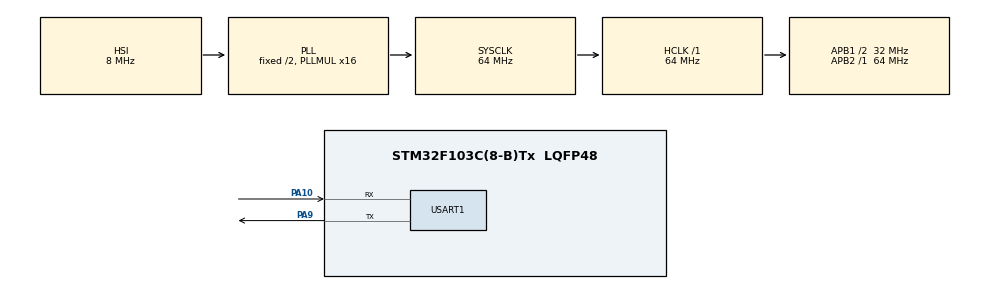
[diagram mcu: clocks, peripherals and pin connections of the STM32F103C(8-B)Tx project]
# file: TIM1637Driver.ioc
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Mcu.Family=STM32F1
Mcu.Name=STM32F103C(8-B)Tx
Mcu.Package=LQFP48
NVIC.PriorityGroup=NVIC_PRIORITYGROUP_4
PA10.Mode=Asynchronous
PA10.Signal=USART1_RX
PA13.Mode=Serial_Wire
PA13.Signal=SYS_JTMS-SWDIO
PA14.Mode=Serial_Wire
PA14.Signal=SYS_JTCK-SWCLK
PA9.Mode=Asynchronous
PA9.Signal=USART1_TX
PC14-OSC32_IN.Mode=LSE-External-Oscillator
PC14-OSC32_IN.Signal=RCC_OSC32_IN
PC15-OSC32_OUT.Mode=LSE-External-Oscillator
PC15-OSC32_OUT.Signal=RCC_OSC32_OUT
ProjectManager.HeapSize=0x200
ProjectManager.StackSize=0x400
ProjectManager.TargetToolchain=Makefile
RCC.AHBFreq_Value=64000000
RCC.APB1CLKDivider=RCC_HCLK_DIV2
RCC.APB1Freq_Value=32000000
RCC.APB1TimFreq_Value=64000000
RCC.APB2Freq_Value=64000000
RCC.APB2TimFreq_Value=64000000
RCC.HCLKFreq_Value=64000000
RCC.PLLMUL=RCC_PLL_MUL16
RCC.SYSCLKFreq_VALUE=64000000
RCC.SYSCLKSource=RCC_SYSCLKSOURCE_PLLCLK
RCC.USBFreq_Value=64000000
USART1.VirtualMode=VM_ASYNC
board=custom

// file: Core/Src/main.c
/* USER CODE BEGIN Header */
/**
  ******************************************************************************
  * @file           : main.c
  * @brief          : Main program body
  ******************************************************************************
  * @attention
  *
  * <h2><center>&copy; Copyright (c) 2024 STMicroelectronics.
  * All rights reserved.</center></h2>
  *
  * This software component is licensed by ST under BSD 3-Clause license,
  * the "License"; You may not use this file except in compliance with the
  * License. You may obtain a copy of the License at:
  *                        opensource.org/licenses/BSD-3-Clause
  *
  ******************************************************************************
  */
/* USER CODE END Header */
#include "main.h"

/* USER CODE BEGIN Includes */
#include "tim1637.h"
#include <string.h>
#include <stdio.h>
/* USER CODE END Includes */

UART_HandleTypeDef huart1;

void SystemClock_Config(void);
static void MX_GPIO_Init(void);
static void MX_USART1_UART_Init(void);

/* USER CODE BEGIN 0 */
void config_my_tim(CCGPIO* CLK, CCGPIO* DIO){
    createGPIO(CLK, GPIOB, GPIO_PIN_6, 'B');
    createGPIO(DIO, GPIOB, GPIO_PIN_7, 'B');
    CCGPIOConfig config;
    createGPIOConfig(&config, GPIO_SPEED_FREQ_HIGH, GPIO_NOPULL, GPIO_MODE_OUTPUT_PP);
    setGPIOConfig(CLK, &config);
    setGPIOConfig(DIO, &config);
}

void config_my_tim2(CCGPIO* CLK, CCGPIO* DIO){
    createGPIO(CLK, GPIOA, GPIO_PIN_6, 'A');
    createGPIO(DIO, GPIOA, GPIO_PIN_7, 'A');
    CCGPIOConfig config;
    createGPIOConfig(&config, GPIO_SPEED_FREQ_HIGH, GPIO_NOPULL, GPIO_MODE_OUTPUT_PP);
    setGPIOConfig(CLK, &config);
    setGPIOConfig(DIO, &config);
}

void adjust_num(uint8_t disp[]){
  // the two and third one is seconds
  disp[3]++;
  if(disp[3] >= 10){
    disp[2] += 1;
    disp[3] = 0;
  }

  if(disp[2] >= 6)
  {
    disp[1] += 1;
    disp[2] = 0;
  }

    if(disp[1] >= 10){
    disp[0] += 1;
    disp[1] = 0;
  }
}

/* USER CODE END 0 */

int main(void)
{

  /* MCU Configuration--------------------------------------------------------*/

  /* Reset of all peripherals, Initializes the Flash interface and the Systick. */
  HAL_Init();

  /* Configure the system clock */
  SystemClock_Config();

  /* Initialize all configured peripherals */
  MX_GPIO_Init();
  MX_USART1_UART_Init();

  /* Infinite loop */
  /* USER CODE BEGIN WHILE */

  DisplayArray arr;
  CCGPIO CLK, DIO, CLK2, DIO2;
  CCTIM1637_Handle handle, handle2;
  config_my_tim(&CLK, &DIO);
  config_my_tim2(&CLK2, &DIO2);
  init_cctim1637(&handle, &CLK, &DIO);
  init_cctim1637(&handle2, &CLK2, &DIO2);
  set_TIM1637_Brightness(&handle, 7);
  set_TIM1637_Brightness(&handle2, 3);
  uint8_t shell_disp = 1;
  uint8_t disp_num[4] = {0, 0, 0, 0};
  while (1)
  {
    /* USER CODE END WHILE */

    /* USER CODE BEGIN 3 */
    set_display_array_at_index(disp_num[0] , arr, 0);
    set_display_array_at_index(disp_num[1], arr, 1);
    set_accuired_disp_colon(arr, shell_disp);
    set_display_array_at_index(disp_num[2], arr, 2);
    set_display_array_at_index(disp_num[3], arr, 3);
    commit_display_auto_upgrade(&handle, arr);
    commit_display_auto_upgrade(&handle2, arr);
    HAL_Delay(1000);
    shell_disp = !shell_disp;
    adjust_num(disp_num);
  }
  /* USER CODE END 3 */
}

void SystemClock_Config(void)
{
  RCC_OscInitTypeDef RCC_OscInitStruct = {0};
  RCC_ClkInitTypeDef RCC_ClkInitStruct = {0};

  /** Initializes the RCC Oscillators according to the specified parameters
  * in the RCC_OscInitTypeDef structure.
  */
  RCC_OscInitStruct.OscillatorType = RCC_OSCILLATORTYPE_HSI;
  RCC_OscInitStruct.HSIState = RCC_HSI_ON;
  RCC_OscInitStruct.HSICalibrationValue = RCC_HSICALIBRATION_DEFAULT;
  RCC_OscInitStruct.PLL.PLLState = RCC_PLL_ON;
  RCC_OscInitStruct.PLL.PLLSource = RCC_PLLSOURCE_HSI_DIV2;
  RCC_OscInitStruct.PLL.PLLMUL = RCC_PLL_MUL16;
  if (HAL_RCC_OscConfig(&RCC_OscInitStruct) != HAL_OK)
  {
    Error_Handler();
  }
  /** Initializes the CPU, AHB and APB buses clocks
  */
  RCC_ClkInitStruct.ClockType = RCC_CLOCKTYPE_HCLK|RCC_CLOCKTYPE_SYSCLK
                              |RCC_CLOCKTYPE_PCLK1|RCC_CLOCKTYPE_PCLK2;
  RCC_ClkInitStruct.SYSCLKSource = RCC_SYSCLKSOURCE_PLLCLK;
  RCC_ClkInitStruct.AHBCLKDivider = RCC_SYSCLK_DIV1;
  RCC_ClkInitStruct.APB1CLKDivider = RCC_HCLK_DIV2;
  RCC_ClkInitStruct.APB2CLKDivider = RCC_HCLK_DIV1;

  if (HAL_RCC_ClockConfig(&RCC_ClkInitStruct, FLASH_LATENCY_2) != HAL_OK)
  {
    Error_Handler();
  }
}

static void MX_USART1_UART_Init(void)
{

  huart1.Instance = USART1;
  huart1.Init.BaudRate = 115200;
  huart1.Init.WordLength = UART_WORDLENGTH_8B;
  huart1.Init.StopBits = UART_STOPBITS_1;
  huart1.Init.Parity = UART_PARITY_NONE;
  huart1.Init.Mode = UART_MODE_TX_RX;
  huart1.Init.HwFlowCtl = UART_HWCONTROL_NONE;
  huart1.Init.OverSampling = UART_OVERSAMPLING_16;
  if (HAL_UART_Init(&huart1) != HAL_OK)
  {
    Error_Handler();
  }

}

static void MX_GPIO_Init(void)
{

  /* GPIO Ports Clock Enable */
  __HAL_RCC_GPIOC_CLK_ENABLE();
  __HAL_RCC_GPIOA_CLK_ENABLE();

}

void Error_Handler(void)
{
  __disable_irq();
  while (1)
  {
  }
}

/************************ (C) COPYRIGHT STMicroelectronics *****END OF FILE****/
